# STM32L4P5AEI6 register map
File version: 1.0
Registers are 32-bit, access not given, reset 0x0 unless marked. A register's access mark holds for its fields unless they carry their own. Offsets are from the block's base; [hi:lo] are bit positions; {n}, {i} and the like mark numbered series; 'fields as' and 'values as' point back to an identical list.

## DMA1
Base 0x40020000
Same registers: DMA2 0x40020400
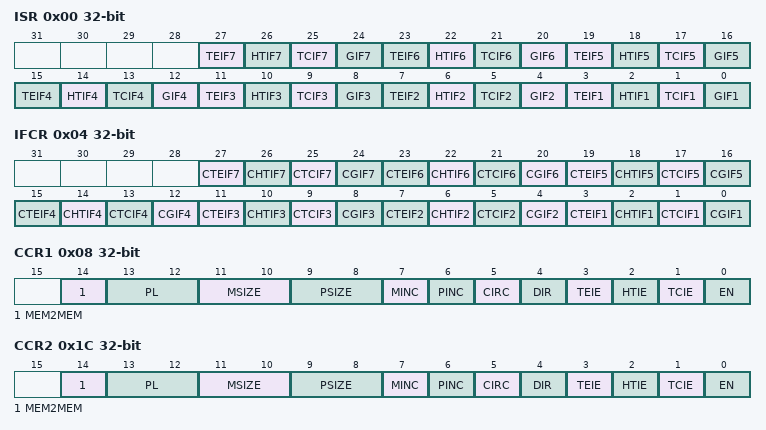
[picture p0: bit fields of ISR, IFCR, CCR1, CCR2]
0x00 ISR
  [4n-1] TEIF{n} (n=1..7), [4n-2] HTIF{n} (n=1..7), [4n-3] TCIF{n} (n=1..7), [4n-4] GIF{n} (n=1..7)
0x04 IFCR
  [4n-1] CTEIF{n} (n=1..7), [4n-2] CHTIF{n} (n=1..7), [4n-3] CTCIF{n} (n=1..7), [4n-4] CGIF{n} (n=1..7)
0x08 CCR1
  [14] MEM2MEM, [13:12] PL, [11:10] MSIZE, [9:8] PSIZE, [7] MINC, [6] PINC, [5] CIRC, [4] DIR, [3] TEIE, [2] HTIE, [1] TCIE, [0] EN
0x0C CNDTR1
  [15:0] NDTR
0x10 CPAR1
  [31:0] PA
{0x0+0x14*i} CMAR{i} (i=1..7)
  [31:0] MA
0x1C CCR2
  fields as CCR1
0x20 CNDTR2
  [15:0] NDTR
0x24 CPAR2
  [31:0] PA
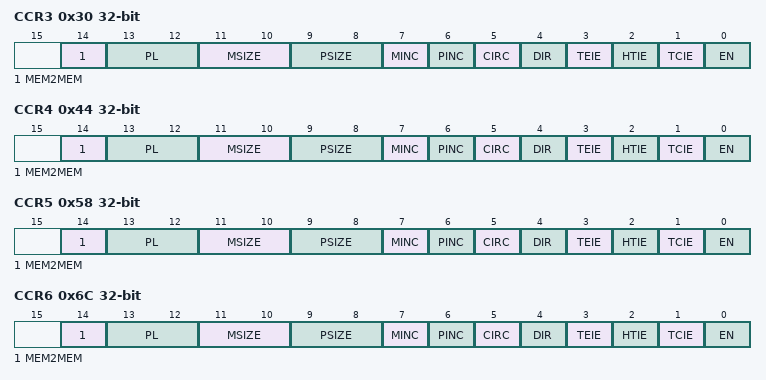
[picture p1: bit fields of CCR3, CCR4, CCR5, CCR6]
0x30 CCR3
  fields as CCR1
0x34 CNDTR3
  [15:0] NDTR
0x38 CPAR3
  [31:0] PA
0x44 CCR4
  fields as CCR1
0x48 CNDTR4
  [15:0] NDTR
0x4C CPAR4
  [31:0] PA
0x58 CCR5
  fields as CCR1
0x5C CNDTR5
  [15:0] NDTR
0x60 CPAR5
  [31:0] PA
0x6C CCR6
  fields as CCR1
0x70 CNDTR6
  [15:0] NDTR
0x74 CPAR6
  [31:0] PA
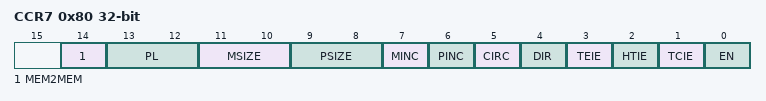
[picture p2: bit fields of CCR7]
0x80 CCR7
  fields as CCR1
0x84 CNDTR7
  [15:0] NDTR
0x88 CPAR7
  [31:0] PA

## DMAMUX1
Base 0x40020800
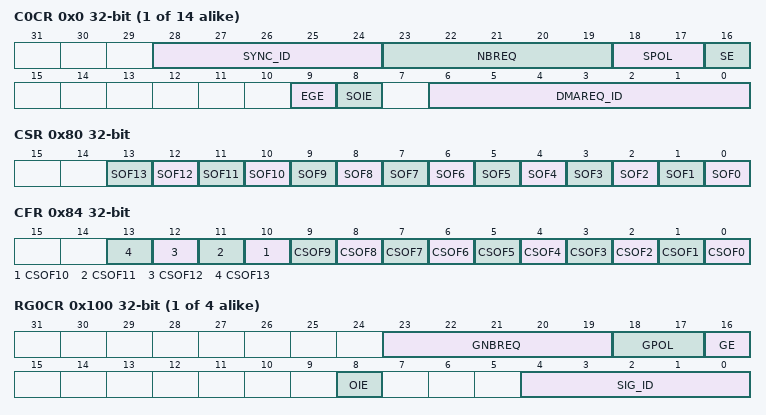
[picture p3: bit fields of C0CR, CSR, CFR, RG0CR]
{0x0+4i} C{i}CR (i=0..13)
  [28:24] SYNC_ID, [23:19] NBREQ, [18:17] SPOL, [16] SE, [9] EGE, [8] SOIE, [6:0] DMAREQ_ID
0x80 CSR
  [n] SOF{n} (n=0..13)
0x84 CFR
  [n] CSOF{n} (n=0..13)
{0x100+4i} RG{i}CR (i=0..3)
  [23:19] GNBREQ, [18:17] GPOL, [16] GE, [8] OIE, [4:0] SIG_ID
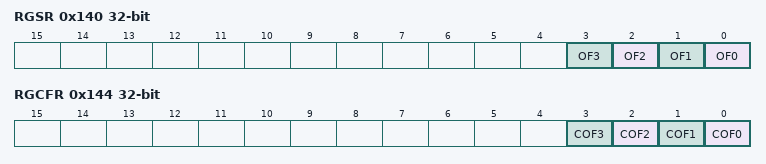
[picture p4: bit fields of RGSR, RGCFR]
0x140 RGSR
  [n] OF{n} (n=0..3)
0x144 RGCFR
  [n] COF{n} (n=0..3)

## FLASH
Base 0x40022000
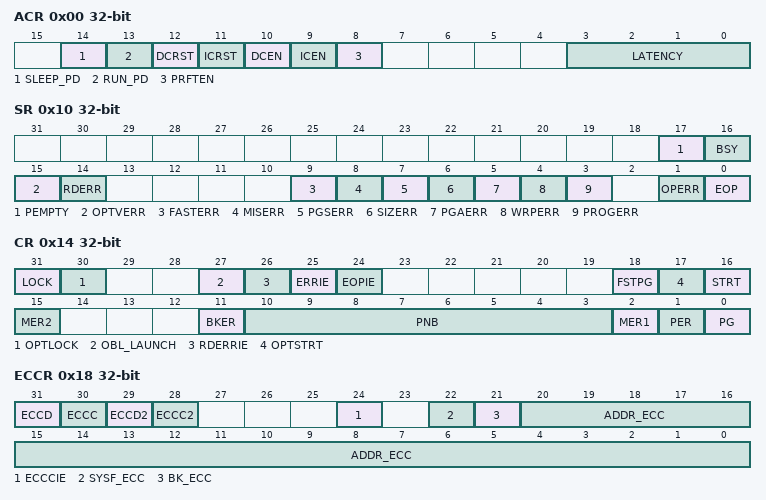
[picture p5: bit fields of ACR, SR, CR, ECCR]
0x00 ACR
  [14] SLEEP_PD, [13] RUN_PD, [12] DCRST, [11] ICRST, [10] DCEN, [9] ICEN, [8] PRFTEN, [3:0] LATENCY
0x04 PDKEYR
0x08 KEYR
0x0C OPTKEYR
0x10 SR
  [17] PEMPTY, [16] BSY, [15] OPTVERR, [14] RDERR, [9] FASTERR, [8] MISERR, [7] PGSERR, [6] SIZERR, [5] PGAERR, [4] WRPERR, [3] PROGERR, [1] OPERR, [0] EOP
0x14 CR
  [31] LOCK, [30] OPTLOCK, [27] OBL_LAUNCH, [26] RDERRIE, [25] ERRIE, [24] EOPIE, [18] FSTPG, [17] OPTSTRT, [16] STRT, [15] MER2, [11] BKER, [10:3] PNB, [2] MER1, [1] PER, [0] PG
0x18 ECCR
  [31] ECCD, [30] ECCC, [29] ECCD2, [28] ECCC2, [24] ECCCIE, [22] SYSF_ECC, [21] BK_ECC, [20:0] ADDR_ECC
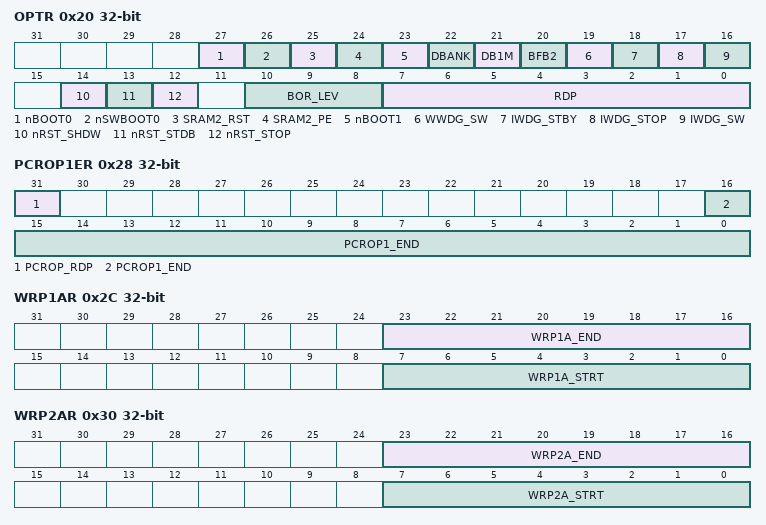
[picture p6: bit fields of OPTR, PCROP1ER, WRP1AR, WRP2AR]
0x20 OPTR
  [27] nBOOT0, [26] nSWBOOT0, [25] SRAM2_RST, [24] SRAM2_PE, [23] nBOOT1, [22] DBANK, [21] DB1M, [20] BFB2, [19] WWDG_SW, [18] IWDG_STBY, [17] IWDG_STOP, [16] IWDG_SW, [14] nRST_SHDW, [13] nRST_STDB, [12] nRST_STOP, [10:8] BOR_LEV, [7:0] RDP
0x24 PCROP1SR
  [16:0] PCROP1_STRT
0x28 PCROP1ER
  [31] PCROP_RDP, [16:0] PCROP1_END
0x2C WRP1AR
  [23:16] WRP1A_END, [7:0] WRP1A_STRT
0x30 WRP2AR
  [23:16] WRP2A_END, [7:0] WRP2A_STRT
0x44 PCROP2SR
  [16:0] PCROP2_STRT
0x48 PCROP2ER
  [16:0] PCROP2_END
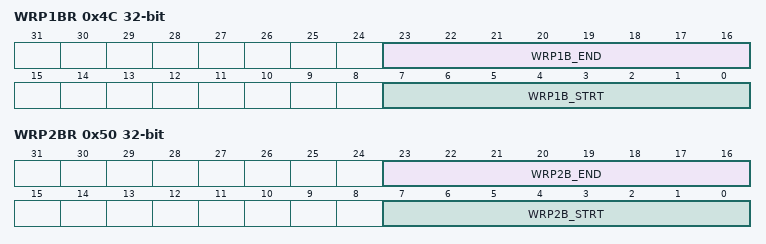
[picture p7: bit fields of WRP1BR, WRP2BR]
0x4C WRP1BR
  [23:16] WRP1B_END, [7:0] WRP1B_STRT
0x50 WRP2BR
  [23:16] WRP2B_END, [7:0] WRP2B_STRT
0x130 CFGR
  [0] LVEN

## CRC
Base 0x40023000
0x00 DR
0x04 IDR
  [7:0] IDR
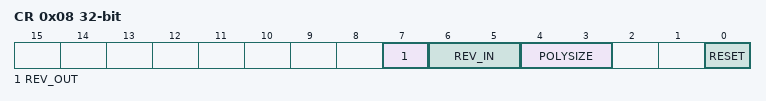
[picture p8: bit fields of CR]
0x08 CR
  [7] REV_OUT, [6:5] REV_IN, [4:3] POLYSIZE, [0] RESET
0x10 INIT
  [31:0] CRC_INIT
0x14 POL

## TSC
Base 0x40024000
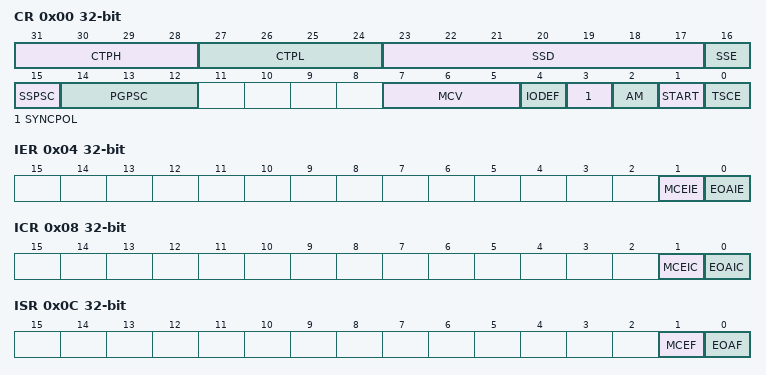
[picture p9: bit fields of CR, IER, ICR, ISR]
0x00 CR
  [31:28] CTPH, [27:24] CTPL, [23:17] SSD, [16] SSE, [15] SSPSC, [14:12] PGPSC, [7:5] MCV, [4] IODEF, [3] SYNCPOL, [2] AM, [1] START, [0] TSCE
0x04 IER
  [1] MCEIE, [0] EOAIE
0x08 ICR
  [1] MCEIC, [0] EOAIC
0x0C ISR
  [1] MCEF, [0] EOAF
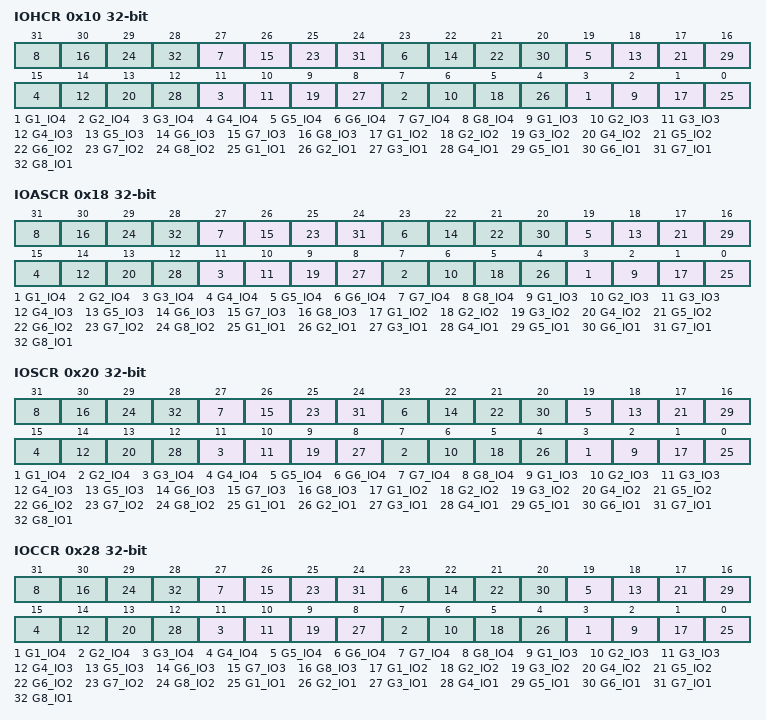
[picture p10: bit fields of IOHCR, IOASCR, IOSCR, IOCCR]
0x10 IOHCR
  [4n-1] G{n}_IO4 (n=1..8), [4n-2] G{n}_IO3 (n=1..8), [4n-3] G{n}_IO2 (n=1..8), [4n-4] G{n}_IO1 (n=1..8)
0x18 IOASCR
  fields as IOHCR
0x20 IOSCR
  fields as IOHCR
0x28 IOCCR
  fields as IOHCR
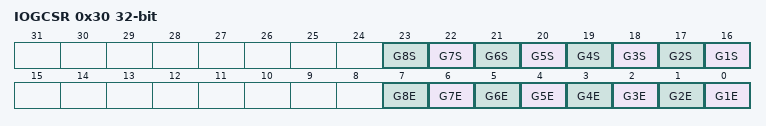
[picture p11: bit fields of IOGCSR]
0x30 IOGCSR
  [n+15] G{n}S (n=1..8), [n-1] G{n}E (n=1..8)
{0x30+4i} IOG{i}CR (i=1..8)
  [13:0] CNT

## GPIOA
Base 0x48000000
Same registers: GPIOB 0x48000400, GPIOC 0x48000800, GPIOD 0x48000C00, GPIOE 0x48001000, GPIOF 0x48001400, GPIOG 0x48001800, GPIOH 0x48001C00, GPIOI 0x48002000
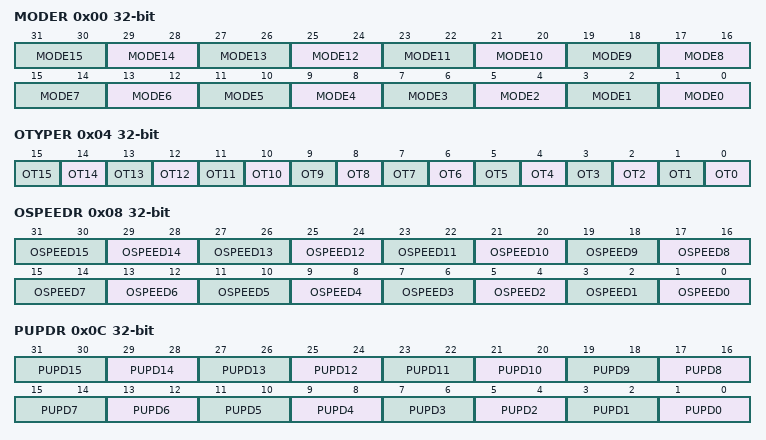
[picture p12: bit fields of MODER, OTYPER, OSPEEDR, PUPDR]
0x00 MODER
  [2n+1:2n] MODE{n} (n=0..15)
0x04 OTYPER
  [n] OT{n} (n=0..15)
0x08 OSPEEDR
  [2n+1:2n] OSPEED{n} (n=0..15)
0x0C PUPDR
  [2n+1:2n] PUPD{n} (n=0..15)
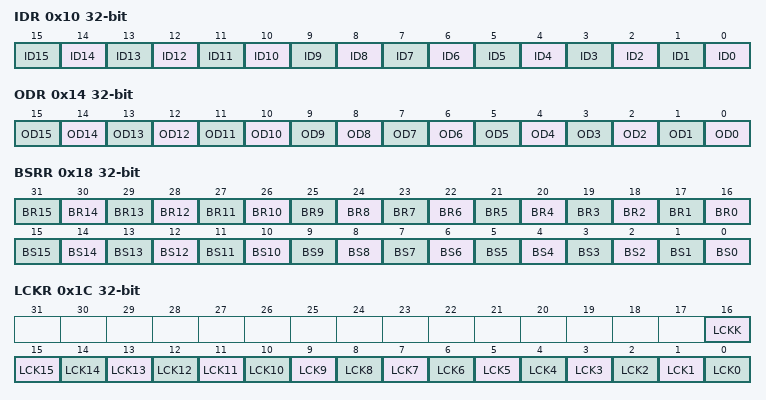
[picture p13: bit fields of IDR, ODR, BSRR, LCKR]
0x10 IDR
  [n] ID{n} (n=0..15)
0x14 ODR
  [n] OD{n} (n=0..15)
0x18 BSRR
  [n+16] BR{n} (n=0..15), [n] BS{n} (n=0..15)
0x1C LCKR
  [16] LCKK, [n] LCK{n} (n=0..15)
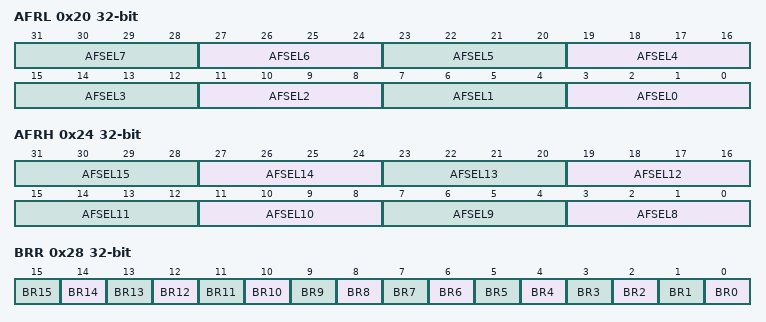
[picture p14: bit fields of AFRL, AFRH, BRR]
0x20 AFRL
  [4n+3:4n] AFSEL{n} (n=0..7)
0x24 AFRH
  [4n-29:4n-32] AFSEL{n} (n=8..15)
0x28 BRR
  [n] BR{n} (n=0..15)
